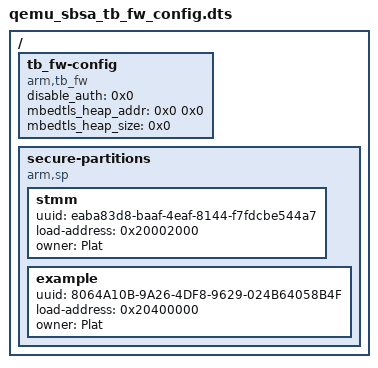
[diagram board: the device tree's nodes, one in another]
/*
 * Copyright (c) 2022, ARM Limited and Contributors. All rights reserved.
 *
 * SPDX-License-Identifier: BSD-3-Clause
 */

 /dts-v1/;

 / {
   tb_fw-config {
     compatible = "arm,tb_fw";

     /* Disable authentication for development */
     disable_auth = <0x0>;

     /*
      * The following two entries are placeholders for Mbed TLS
      * heap information. The default values don't matter since
      * they will be overwritten by BL1.
      * In case of having shared Mbed TLS heap between BL1 and BL2,
      * BL1 will populate these two properties with the respective
      * info about the shared heap. This info will be available for
      * BL2 in order to locate and re-use the heap.
      */
     mbedtls_heap_addr = <0x0 0x0>;
     mbedtls_heap_size = <0x0>;
   };

   secure-partitions {
     compatible = "arm,sp";
     stmm {
      uuid = "eaba83d8-baaf-4eaf-8144-f7fdcbe544a7";
      load-address = <0x20002000>;
      owner = "Plat";
    };
    example {
      uuid = "8064A10B-9A26-4DF8-9629-024B64058B4F";
      load-address = <0x20400000>;
      owner = "Plat";
    };
   };
 };
